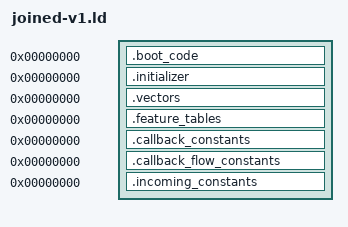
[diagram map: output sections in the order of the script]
OUTPUT_ARCH(riscv)
SECTIONS
{
 .boot_code 0 : SUBALIGN(2) { *(.boot_code)
  *(.text.tsl9_incoming_entry_85c8)
  *(.text.tsl9_incoming_block_85d0)
  *(.text.tsl9_incoming_block_85d8)
  *(.text.tsl9_incoming_block_85da)
  *(.text.tsl9_incoming_block_85e6)
  *(.text.tsl9_incoming_block_85e8)
  *(.text.tsl9_incoming_block_85f0)
  *(.text.tsl9_incoming_block_860e)
  *(.text.tsl9_incoming_block_8612)
  *(.text.tsl9_incoming_entry_888c)
  *(.text.tsl9_incoming_block_8898)
  *(.text.tsl9_incoming_block_88a2)
  *(.text.tsl9_incoming_block_88a6)
  *(.text.tsl9_incoming_block_88be)
  *(.text.tsl9_incoming_block_88ca)
  *(.text.tsl9_incoming_block_88d8)
  *(.text.tsl9_incoming_block_88e4)
  *(.text.tsl9_incoming_block_8908)
  *(.text.tsl9_incoming_block_891a)
  *(.text.tsl9_incoming_block_891e)
  *(.text.tsl9_incoming_block_8938)
  *(.text.tsl9_incoming_block_8942)
  *(.text.tsl9_incoming_block_8962)
  *(.text.tsl9_incoming_block_8970)
  *(.text.tsl9_incoming_block_8978)
  *(.text.tsl9_incoming_block_897e)
  *(.text.tsl9_incoming_block_8982)
  *(.text.tsl9_incoming_block_8986)
  *(.text.tsl9_incoming_block_898e)
  *(.text.tsl9_incoming_block_899a)
  *(.text.tsl9_incoming_block_899e)
  *(.text.tsl9_incoming_block_89a8)
  *(.text.tsl9_incoming_block_89b4)
  *(.text.tsl9_incoming_block_89b8)
  *(.text.tsl9_incoming_block_89c8)
  *(.text.tsl9_incoming_block_89cc)
  *(.text.tsl9_incoming_block_89dc)
  *(.text.tsl9_incoming_block_89e0)
  *(.text.tsl9_incoming_block_89e8)
  *(.text.tsl9_incoming_block_89ea)
  *(.text.tsl9_incoming_block_89f0)
  *(.text.tsl9_incoming_block_89f6)
  *(.text.tsl9_incoming_block_89fa)
  *(.text.tsl9_incoming_block_8a06)
  *(.text.tsl9_incoming_block_8a28)
  *(.text.tsl9_incoming_block_8a2a)
  *(.text.tsl9_incoming_block_8a2e)
  *(.text.tsl9_incoming_block_8a36)
  *(.text.tsl9_incoming_block_8a4c)
  *(.text.tsl9_incoming_block_8a52)
  *(.text.tsl9_incoming_entry_8b90)
  *(.text.tsl9_incoming_block_8b96)
  *(.text.tsl9_incoming_block_8ba6)
  *(.text.tsl9_incoming_block_8bac)
  *(.text.tsl9_incoming_block_8bb6)
  *(.text.tsl9_incoming_block_8bc6)
  *(.text.tsl9_incoming_block_8bce)
  *(.text.tsl9_incoming_block_8bd8)
  *(.text.tsl9_incoming_block_8be2)
  *(.text.tsl9_incoming_block_8be4)
  *(.text.tsl9_incoming_block_8c00)
  *(.text.tsl9_incoming_block_8c18)
  *(.text.tsl9_incoming_block_8c26)
  *(.text.tsl9_incoming_block_8c30)
  *(.text.tsl9_incoming_block_8c32)
  *(.text.tsl9_incoming_block_8c38)
  *(.text.tsl9_incoming_block_8c3a)
  *(.text.tsl9_incoming_block_8c3e)
  *(.text.tsl9_incoming_block_8c48)
  *(.text.tsl9_incoming_block_8c54)
  *(.text.tsl9_incoming_block_8c5c)
  *(.text.tsl9_incoming_block_8c5e)
  *(.text.tsl9_incoming_block_8c70)
  *(.text.tsl9_incoming_block_8c7a)
  *(.text.tsl9_incoming_block_8c7c)
  *(.text.tsl9_incoming_block_8c80)
 }
 .initializer 0 : SUBALIGN(4) { *(.initializer) }
 .vectors 0 : SUBALIGN(4) { *(.vectors) }
 .feature_tables 0 : SUBALIGN(4) { *(.feature_tables) }
 .callback_constants 0 : SUBALIGN(4) { *(.callback_constants) }
 .callback_flow_constants 0 : SUBALIGN(4) { *(.callback_flow_constants) }
 .incoming_constants 0 : ALIGN(4) SUBALIGN(1) {
  *(.rodata.tsl9_incoming_table_prefix_19de0)
  *(.rodata.tsl9_incoming_table_prefix_19dfc)
  *(.rodata.tsl9_incoming_payload_prefix_19dec)
  *(.rodata.tsl9_incoming_lookup_1ab34)
 }
 /DISCARD/ : { *(.comment) *(.riscv.attributes) *(.llvm_addrsig) }
}
